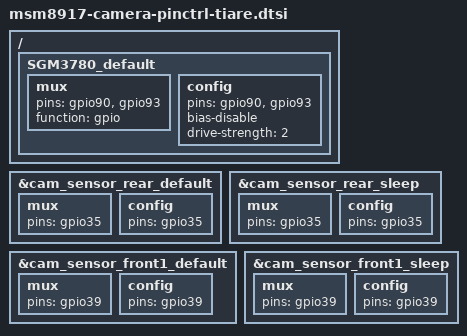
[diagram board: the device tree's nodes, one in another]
/*
 * Copyright (c) 2015, The Linux Foundation. All rights reserved.
 *
 * This program is free software; you can redistribute it and/or modify
 * it under the terms of the GNU General Public License version 2 and
 * only version 2 as published by the Free Software Foundation.
 *
 * This program is distributed in the hope that it will be useful,
 * but WITHOUT ANY WARRANTY; without even the implied warranty of
 * MERCHANTABILITY or FITNESS FOR A PARTICULAR PURPOSE.  See the
 * GNU General Public License for more details.
 */

&cam_sensor_rear_default {
	mux {
		pins = "gpio35";
	};

	config {
		pins = "gpio35";
	};
};

&cam_sensor_rear_sleep {
	mux {
		pins = "gpio35";
	};

	config {
		pins = "gpio35";
	};
};

&cam_sensor_front1_default {
	mux {
		pins = "gpio39";
	};

	config {
		pins = "gpio39";
	};
};

&cam_sensor_front1_sleep {
	mux {
		pins = "gpio39";
	};

	config {
		pins = "gpio39";
	};
};

/ {
	SGM3780_default: SGM3780_default {
		mux {
			pins = "gpio90", "gpio93";
			function = "gpio";
		};

		config {
			pins = "gpio90", "gpio93";
			bias-disable; /* No PULL */
			drive-strength = <2>; /* 2 MA */
		};
	};
};
